# f28004x_pga_regs register map
Vendor: Texas Instruments
Peripheral module from a debugger description file (folder C2000).
Address unit: 16 bits
Registers are 16-bit, read-write, no defined reset value unless marked. A register's access mark holds for its fields unless they carry their own. Offsets are as the file gives them; lines under a group give offsets from that group; [hi:lo] are bit positions; {n}, {i} and the like mark numbered series; 'fields as' and 'values as' point back to an identical list; <NAME> marks a mode.

## PGA_REGS — PGA Registers
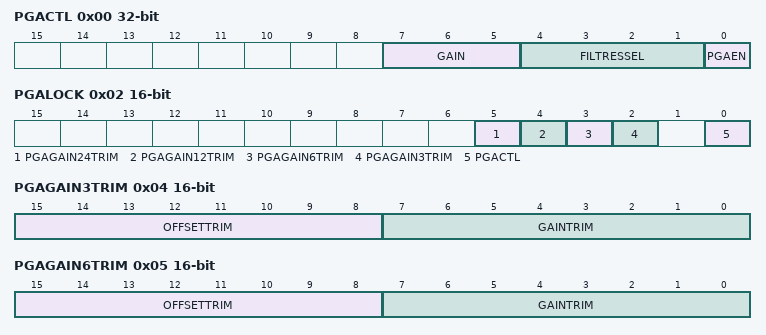
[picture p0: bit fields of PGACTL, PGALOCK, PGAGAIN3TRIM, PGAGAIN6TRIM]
0x00 PGACTL 32-bit — PGA Control Register
  [7:5] GAIN — PGA gain setting
  [4:1] FILTRESSEL — Filter Resistor Select
  [0] PGAEN — PGA Enable
0x02 PGALOCK access not given
  [5] PGAGAIN24TRIM — Lock bit for PGAGAIN24TRIM. (access SOnce)
  [4] PGAGAIN12TRIM — Lock bit for PGAGAIN12TRIM. (access SOnce)
  [3] PGAGAIN6TRIM — Lock bit for PGAGAIN6TRIM. (access SOnce)
  [2] PGAGAIN3TRIM — Lock bit for PGAGAIN3TRIM. (access SOnce)
  [0] PGACTL — Lock bit for PGACTL. (access SOnce)
0x04 PGAGAIN3TRIM — PGA Gain Trim Register for a gain setting of 3
  [15:8] OFFSETTRIM — OFFSET TRIM value, when Gain setting is 3
  [7:0] GAINTRIM — Gain TRIM value, when gain setting is 3
0x05 PGAGAIN6TRIM — PGA Gain Trim Register for a gain setting of 6
  [15:8] OFFSETTRIM — OFFSET TRIM value, when Gain setting is 6
  [7:0] GAINTRIM — Gain TRIM value, when gain setting is 6
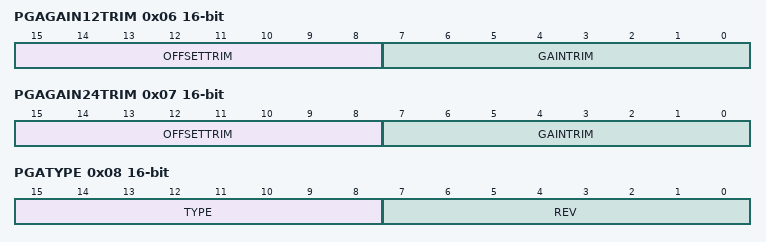
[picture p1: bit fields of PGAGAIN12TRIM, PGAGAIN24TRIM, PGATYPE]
0x06 PGAGAIN12TRIM — PGA Gain Trim Register for a gain setting of 12
  [15:8] OFFSETTRIM — OFFSET TRIM value, when Gain setting is 12
  [7:0] GAINTRIM — Gain TRIM value, when gain setting is 12
0x07 PGAGAIN24TRIM — PGA Gain Trim Register for a gain setting of 24
  [15:8] OFFSETTRIM — OFFSET TRIM value, when Gain setting is 24
  [7:0] GAINTRIM — Gain TRIM value, when gain setting is 24
0x08 PGATYPE ro
  [15:8] TYPE — PGA Type Field
  [7:0] REV — PGA Revision Field
